# NANO100AN_v1 register map
File version: 1.0
Registers are 32-bit, read-write, reset 0x0 unless marked. A register's access mark holds for its fields unless they carry their own. Offsets are from the block's base; [hi:lo] are bit positions; lines under a group give offsets from that group; {n}, {i} and the like mark numbered series.

## SCS — SCS Register Map
Base 0xE000E000
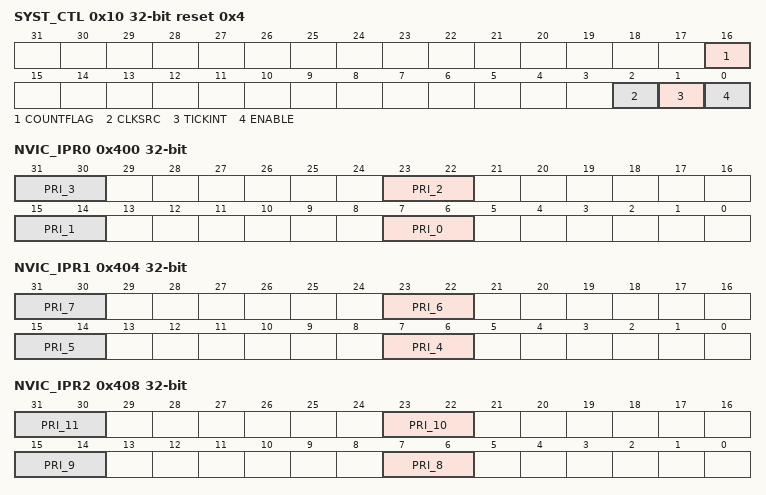
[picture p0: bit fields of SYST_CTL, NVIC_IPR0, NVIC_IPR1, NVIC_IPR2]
0x10 SYST_CTL reset 0x4 — SysTick Control and Status
  [16] COUNTFLAG — Returns 1 If Timer Counted To 0 Since Last Time This Register Was Read. COUNTFLAG is set by a count transition from 1 to 0. COUNTFLAG is cleared on read or by a write to the Current Value register.
  [2] CLKSRC
    0=Clock Source is (optional) external reference clock; 1=Core clock used for SysTick If no external clock provided, this bit will read as 1 and ignore writes
  [1] TICKINT
    0=Counting down to 0 does not cause the SysTick exception to be pended. Software can use COUNTFLAG to determine if a count to zero has occurred; 1=Counting down to 0 will cause the SysTick exception to be pended. Clearing the SysTick Current Value register by a register write in software will not cause SysTick to be pended
  [0] ENABLE
    0=The counter is Disabled; 1=The counter will operate in a multi-shot manner
0x14 SYST_RVR reset not defined — SysTick Reload Value Register
  [23:0] RELOAD — The value to load into the Current Value register when the counter reaches 0.
0x18 SYST_CVR reset not defined — SysTick Current Value
  [23:0] CURRENT — Current Counter Value. This is the value of the counter at the time it is sampled. The counter does not provide read-modify-write protection. The register is write-clear. A software write of any value will clear the register to 0. Unsupported bits RAZ (Read As Zero, writes ignore) (See SysTick Reload Value register).
0x100 NVIC_ISER — IRQ0~IRQ31 Set-enable Control Register
  [31:0] SETENA — Enable one or more interrupts within a group of 32. Each Bit Represents An Interrupt Number From IRQ0 ~ IRQ31 (Vector Number From 16 ~ 47). Writing 1 will enable the associated interrupt. Writing 0 has no effect. The register reads back with the current enable state.
0x180 NVIC_ICER — IRQ0~IRQ31 Clear-enable Control Register
  [31:0] CLRENA — Disable one or more interrupts within a group of 32. Each Bit Represents An Interrupt Number From IRQ0 ~ IRQ31 (Vector Number From 16 ~ 47). Writing 1 will disable the associated interrupt. Writing 0 has no effect. The register reads back with the current enable state.
0x200 NVIC_ISPR — IRQ0~IRQ31 Set-pending Control Register
  [31:0] SETPEND — Writing 1 To A Bit To Set Pending State Of The Associated Interrupt Under Software Control Each bit represents an interrupt number from IRQ0 ~ IRQ31 (Vector number from 16 ~ 47). Writing 0 has no effect. The register reads back with the current pending state.
0x280 NVIC_ICPR — IRQ0~IRQ31 Clear-pending Control Register
  [31:0] CLRPEND — Writing 1 To A Bit To Remove The Pending State Of Associated Interrupt Under Software Control Each bit represents an interrupt number from IRQ0 ~ IRQ31 (Vector number from 16 ~ 47). Writing 0 has no effect. The register reads back with the current pending state.
0x400 NVIC_IPR0 — IRQ0~IRQ3 Priority Control Register
  [8n+7:8n+6] PRI_{n} (n=0..3) — Priority Of IRQ{n} "0" denotes the highest priority and "3" denotes the lowest priority.
0x404 NVIC_IPR1 — IRQ4~IRQ7 Priority Control Register
  [8n-25:8n-26] PRI_{n} (n=4..7) — Priority Of IRQ{n} "0" denotes the highest priority and "3" denotes the lowest priority.
0x408 NVIC_IPR2 — IRQ8~IRQ11 Priority Control Register
  [8n-57:8n-58] PRI_{n} (n=8..11) — Priority Of IRQ{n} "0" denotes the highest priority and "3" denotes the lowest priority.
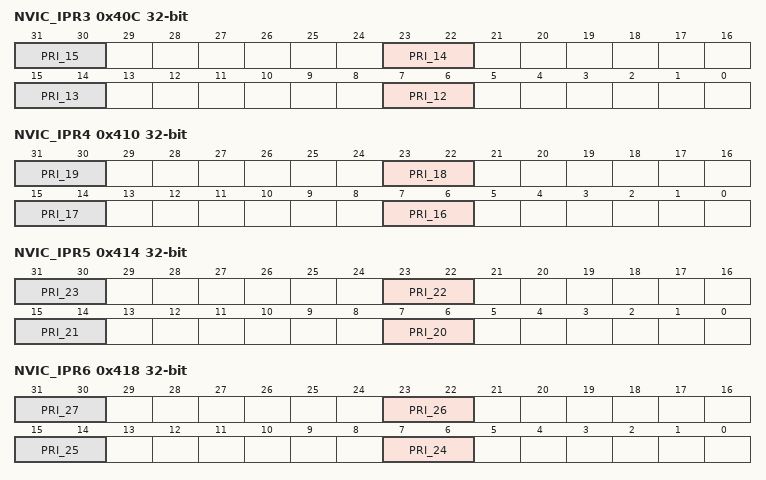
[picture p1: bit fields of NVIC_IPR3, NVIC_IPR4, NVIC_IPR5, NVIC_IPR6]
0x40C NVIC_IPR3 — IRQ12~IRQ15 Priority Control Register
  [8n-89:8n-90] PRI_{n} (n=12..15) — Priority Of IRQ{n} "0" denotes the highest priority and "3" denotes the lowest priority.
0x410 NVIC_IPR4 — IRQ16~IRQ19 Priority Control Register
  [8n-121:8n-122] PRI_{n} (n=16..19) — Priority Of IRQ{n} "0" denotes the highest priority and "3" denotes the lowest priority.
0x414 NVIC_IPR5 — IRQ20~IRQ23 Priority Control Register
  [8n-153:8n-154] PRI_{n} (n=20..23) — Priority Of IRQ{n} "0" denotes the highest priority and "3" denotes the lowest priority.
0x418 NVIC_IPR6 — IRQ24~IRQ27 Priority Control Register
  [8n-185:8n-186] PRI_{n} (n=24..27) — Priority Of IRQ{n} "0" denotes the highest priority and "3" denotes the lowest priority.
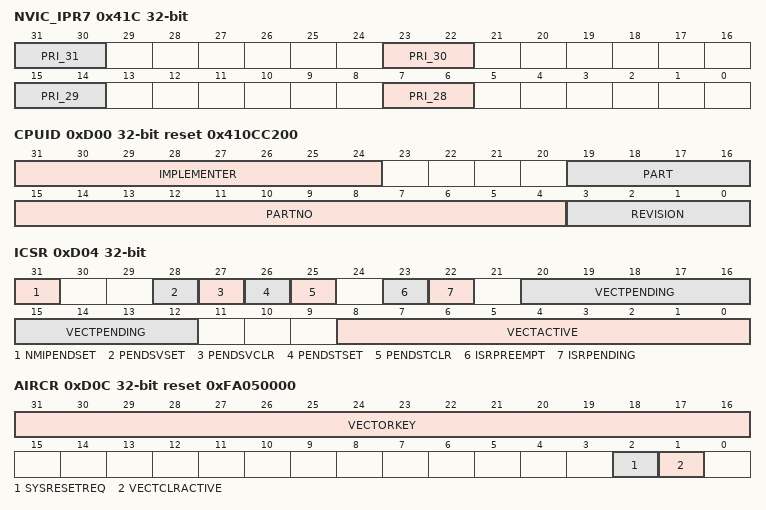
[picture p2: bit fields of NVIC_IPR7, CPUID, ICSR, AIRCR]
0x41C NVIC_IPR7 — IRQ28~IRQ31 Priority Control Register
  [8n-217:8n-218] PRI_{n} (n=28..31) — Priority Of IRQ{n} "0" denotes the highest priority and "3" denotes the lowest priority.
0xD00 CPUID ro reset 0x410CC200 — CPUID Base Register
  [31:24] IMPLEMENTER
  [19:16] PART — Reads as 0xC for ARMv6-M parts
  [15:4] PARTNO — Reads as 0xC20.
  [3:0] REVISION — Reads as 0x0
0xD04 ICSR — Interrupt Control State Register
  [31] NMIPENDSET — Setting This Bit Will Activate An NMI. Since NMI is the highest priority exception, it will activate as soon as it is registered. Reads back with current state (1 if Pending, 0 if not).
  [28] PENDSVSET — Set A Pending PendSV Interrupt. This is normally used to request a context switch. Reads back with current state (1 if Pending, 0 if not).
  [27] PENDSVCLR — Write 1 to clear a pending PendSV interrupt.
  [26] PENDSTSET — Set A Pending SysTick Reads back with current state (1 if Pending, 0 if not).
  [25] PENDSTCLR — Write 1 to clear a pending SysTick.
  [23] ISRPREEMPT — If set, a pending exception will be serviced on exit from the debug halt state.
  [22] ISRPENDING — Indicates if an external configurable (NVIC generated) interrupt is pending.
  [20:12] VECTPENDING — Indicates The Exception Number For The Highest Priority Pending Exception. The pending state includes the effect of memory-mapped enable and mask registers. It does not include the PRIMASK special-purpose register qualifier. A value of zero indicates no pending exceptions.
  [8:0] VECTACTIVE — If value of VECTACTIVE 1: the exception number for the current executing exception.
    0=Thread mode
0xD0C AIRCR reset 0xFA050000 — Application Interrupt and Reset Control Register
  [31:16] VECTORKEY — When write this register, this field should be 0x05FA, otherwise the write action will be unpredictable.
  [2] SYSRESETREQ — Writing This Bit 1 Will Cause A Reset Signal To Be Asserted To The Chip To Indicate A Reset Is Requested. The bit is a write only bit and self-clears as part of the reset sequence.
  [1] VECTCLRACTIVE — Set This Bit To 1 Will Clears All Active State Information For Fixed And Configurable Exceptions. The bit is a write only bit and can only be written when the core is halted. Note: It is the debugger's responsibility to re-initialize the stack.
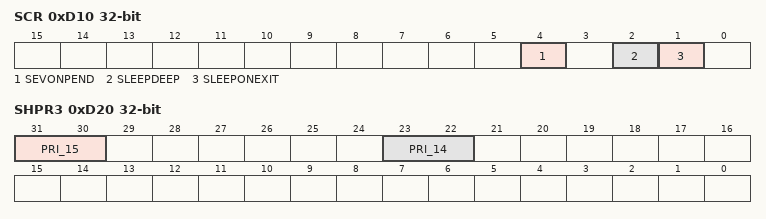
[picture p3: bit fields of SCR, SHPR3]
0xD10 SCR — System Control Register
  [4] SEVONPEND — When enabled, interrupt transitions from Inactive to Pending are included in the list of wake-up events for the WFE instruction.
  [2] SLEEPDEEP — A qualifying hint that indicates waking from sleep might take longer.
  [1] SLEEPONEXIT — When Set To 1, The Core Can Enter A Sleep State On An Exception Return To Thread Mode This is the mode and exception level entered at reset, the base level of execution.
0xD1C SHPR2 — System Handler Priority Register 2
  [31:30] PRI_11 — Priority Of System Handler 11 - SVCall "0" denotes the highest priority and "3" denotes the lowest priority.
0xD20 SHPR3 — System Handler Priority Register 3
  [31:30] PRI_15 — Priority Of System Handler 15 - SysTick "0" denotes the highest priority and "3" denotes the lowest priority.
  [23:22] PRI_14 — Priority Of System Handler 14 - PendSV "0" denotes the highest priority and "3" denotes the lowest priority.
